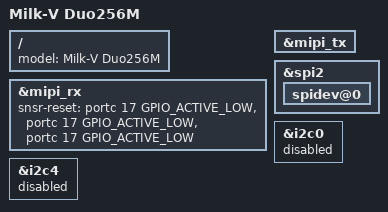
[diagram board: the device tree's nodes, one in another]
/dts-v1/;
#include "cv181x_base_riscv.dtsi"
#include "cv181x_asic_qfn.dtsi"
#include "cv181x_asic_sd.dtsi"
#include "cv181x_default_memmap.dtsi"

&mipi_rx{
	snsr-reset = <&portc 17 GPIO_ACTIVE_LOW>, <&portc 17 GPIO_ACTIVE_LOW>, <&portc 17 GPIO_ACTIVE_LOW>;
};

&mipi_tx {
	/delete-property/ reset-gpio;
	/delete-property/ pwm-gpio;
	/delete-property/ power-ct-gpio;
};

&spi2 {
	status = "okay";

	spidev@0 {
		status = "okay";
	};
};

&i2c0 {
	status = "disabled";
};

&i2c4 {
	status = "disabled";
};

/ {
	model = "Milk-V Duo256M";
};

